# S32K116 register map
Vendor: NXP; Series: S32K; File version: 1.6
CPU: CM0PLUS r0p0, little endian, MPU, FPU, 2 interrupt priority bits
Registers are 32-bit, read-write, reset 0x0 unless marked. A register's access mark holds for its fields unless they carry their own. Offsets are from the block's base; [hi:lo] are bit positions.

## S32_SCB — System Control Registers
Base 0xE000E000; register names take the prefix SCB_
0x08 ACTLR ro — Auxiliary Control Register,
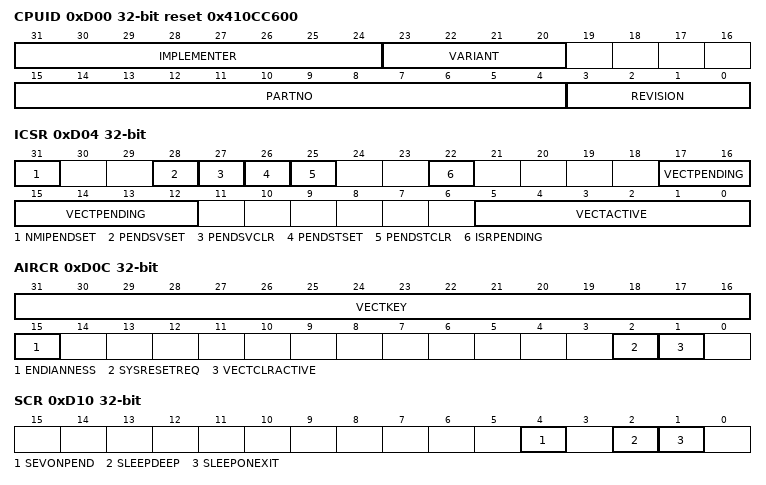
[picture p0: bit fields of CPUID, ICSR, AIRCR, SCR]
0xD00 CPUID ro reset 0x410CC600 — CPUID Base Register
  [31:24] IMPLEMENTER — Implementer code
  [23:20] VARIANT — Indicates processor revision: 0x2 = Revision 2
  [15:4] PARTNO — Indicates part number
  [3:0] REVISION — Indicates patch release: 0x0 = Patch 0
0xD04 ICSR — Interrupt Control and State Register
  [31] NMIPENDSET — NMI set-pending bit
    0=write: no effect; read: NMI exception is not pending; 1=write: changes NMI exception state to pending; read: NMI exception is pending
  [28] PENDSVSET — PendSV set-pending bit
    0=write: no effect; read: PendSV exception is not pending; 1=write: changes PendSV exception state to pending; read: PendSV exception is pending
  [27] PENDSVCLR wo — PendSV clear-pending bit
    0=no effect; 1=removes the pending state from the PendSV exception
  [26] PENDSTSET — SysTick exception set-pending bit
    0=write: no effect; read: SysTick exception is not pending; 1=write: changes SysTick exception state to pending; read: SysTick exception is pending
  [25] PENDSTCLR wo — SysTick exception clear-pending bit
    0=no effect; 1=removes the pending state from the SysTick exception
  [22] ISRPENDING ro — Interrupt pending flag, excluding NMI and Faults
    0=interrupt not pending; 1=interrupt pending
  [17:12] VECTPENDING ro — Exception number of the highest priority pending enabled exception
  [5:0] VECTACTIVE ro — Active exception number
0xD08 VTOR — Vector Table Offset Register
  [31:7] TBLOFF — Vector table base offset
0xD0C AIRCR — Application Interrupt and Reset Control Register
  [31:16] VECTKEY — Register key
  [15] ENDIANNESS ro — Data endianness implemented
    0=Little-endian; 1=Big-endian
  [2] SYSRESETREQ wo — System reset request:
    0=no system reset request; 1=asserts a signal to the outer system that requests a reset
  [1] VECTCLRACTIVE wo — Reserved for debug use. This bit reads as 0. When writing to the register you must write 0 to this bit, otherwise behavior is Unpredictable.
0xD10 SCR — System Control Register
  [4] SEVONPEND — Send Event on Pending bit
    0=only enabled interrupts or events can wakeup the processor, disabled interrupts are excluded; 1=enabled events and all interrupts, including disabled interrupts, can wakeup the processor
  [2] SLEEPDEEP — Controls whether the processor uses sleep or deep sleep as its low power mode
    0=sleep; 1=deep sleep
  [1] SLEEPONEXIT — Indicates sleep-on-exit when returning from Handler mode to Thread mode
    0=o not sleep when returning to Thread mode; 1=enter sleep, or deep sleep, on return from an ISR
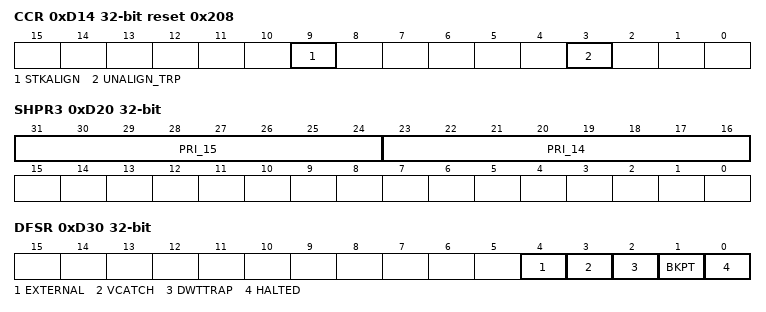
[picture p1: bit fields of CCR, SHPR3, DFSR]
0xD14 CCR ro reset 0x208 — Configuration and Control Register
  [9] STKALIGN — Indicates stack alignment on exception entry
  [3] UNALIGN_TRP — Always reads as one, indicates that all unaligned accesses generate a HardFault
0xD1C SHPR2 — System Handler Priority Register 2
  [31:24] PRI_11 — Priority of system handler 11, SVCall
0xD20 SHPR3 — System Handler Priority Register 3
  [31:24] PRI_15 — Priority of system handler 15, SysTick exception
  [23:16] PRI_14 — Priority of system handler 14, PendSV
0xD24 SHCSR — System Handler Control and State Register
  [15] SVCALLPENDED — SVCall pending bit, reads as 1 if exception is pending
    0=exception is not pending; 1=exception is pending
0xD30 DFSR — Debug Fault Status Register
  [4] EXTERNAL
    0=No EDBGRQ debug event; 1=EDBGRQ debug event
  [3] VCATCH
    0=No Vector catch triggered; 1=Vector catch triggered
  [2] DWTTRAP
    0=No current debug events generated by the DWT; 1=At least one current debug event generated by the DWT
  [1] BKPT
    0=No current breakpoint debug event; 1=At least one current breakpoint debug event
  [0] HALTED
    0=No active halt request debug event; 1=Halt request debug event active

## Notices in the file
Redistribution and use in source and binary forms, with or without modification,
are permitted provided that the following conditions are met:
o Redistributions of source code must retain the above copyright notice, this list
of conditions and the following disclaimer.
o Redistributions in binary form must reproduce the above copyright notice, this
list of conditions and the following disclaimer in the documentation and/or
other materials provided with the distribution.
o Neither the name of Freescale Semiconductor, Inc. nor the names of its
contributors may be used to endorse or promote products derived from this
software without specific prior written permission.
THIS SOFTWARE IS PROVIDED BY THE COPYRIGHT HOLDERS AND CONTRIBUTORS "AS IS" AND
ANY EXPRESS OR IMPLIED WARRANTIES, INCLUDING, BUT NOT LIMITED TO, THE IMPLIED
WARRANTIES OF MERCHANTABILITY AND FITNESS FOR A PARTICULAR PURPOSE ARE
DISCLAIMED. IN NO EVENT SHALL THE COPYRIGHT HOLDER OR CONTRIBUTORS BE LIABLE FOR
ANY DIRECT, INDIRECT, INCIDENTAL, SPECIAL, EXEMPLARY, OR CONSEQUENTIAL DAMAGES
(INCLUDING, BUT NOT LIMITED TO, PROCUREMENT OF SUBSTITUTE GOODS OR SERVICES;
LOSS OF USE, DATA, OR PROFITS; OR BUSINESS INTERRUPTION) HOWEVER CAUSED AND ON
ANY THEORY OF LIABILITY, WHETHER IN CONTRACT, STRICT LIABILITY, OR TORT
(INCLUDING NEGLIGENCE OR OTHERWISE) ARISING IN ANY WAY OUT OF THE USE OF THIS
SOFTWARE, EVEN IF ADVISED OF THE POSSIBILITY OF SUCH DAMAGE.
